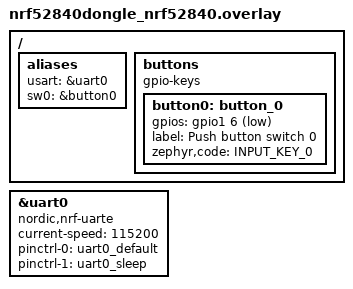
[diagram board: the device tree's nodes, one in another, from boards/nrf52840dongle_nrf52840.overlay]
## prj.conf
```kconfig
CONFIG_GPIO=y
CONFIG_UART_INTERRUPT_DRIVEN=y
CONFIG_STDOUT_CONSOLE=y

CONFIG_SYSTEM_WORKQUEUE_STACK_SIZE=2048

CONFIG_BT_SETTINGS=y
CONFIG_FLASH=y
CONFIG_FLASH_MAP=y
CONFIG_NVS=y
CONFIG_SETTINGS=y
CONFIG_HWINFO=y

CONFIG_BT=y
CONFIG_BT_L2CAP_TX_BUF_COUNT=5
CONFIG_BT_PERIPHERAL=y
CONFIG_BT_OBSERVER=y
CONFIG_BT_BROADCASTER=y

CONFIG_BT_CTLR_DUP_FILTER_LEN=0
CONFIG_BT_CTLR_LE_ENC=n
CONFIG_BT_CTLR_LE_PING=n
CONFIG_BT_DATA_LEN_UPDATE=n
CONFIG_BT_PHY_UPDATE=n
CONFIG_BT_CTLR_MIN_USED_CHAN=n
CONFIG_BT_CTLR_PRIVACY=n
CONFIG_BT_CTLR_CHAN_SEL_2=n

CONFIG_BT_MESH=y
CONFIG_BT_MESH_MODEL_EXTENSIONS=y
CONFIG_BT_MESH_RELAY=y
CONFIG_BT_MESH_FRIEND=y
CONFIG_BT_MESH_PB_GATT=y
CONFIG_BT_MESH_PB_ADV=y
CONFIG_BT_MESH_GATT_PROXY=y

CONFIG_BT_MESH_CFG_CLI=y

#CONFIG_BT_MESH_PROV_OOB_PUBLIC_KEY=y

#CONFIG_BT_MESH_PROV=n
#CONFIG_BT_MESH_PB_ADV=n
#CONFIG_BT_MESH_PB_GATT=n
#CONFIG_BT_MESH_PROV_DEVICE=n
#CONFIG_BT_MESH_PROVISIONER=y

CONFIG_BT_MESH_SUBNET_COUNT=2
CONFIG_BT_MESH_APP_KEY_COUNT=2
CONFIG_BT_MESH_MODEL_GROUP_COUNT=2
CONFIG_BT_MESH_LABEL_COUNT=3
# I don't know if this is all necessary but without it definitely didn't work
```

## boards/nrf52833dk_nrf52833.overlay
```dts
&uart0 {
	compatible = "nordic,nrf-uarte";
	status = "okay";
	current-speed = <115200>;
	pinctrl-0 = <&uart0_default>;
	pinctrl-1 = <&uart0_sleep>;
	pinctrl-names = "default", "sleep";
};

/ {
	aliases {
	usart = &uart0;
	};
};
```

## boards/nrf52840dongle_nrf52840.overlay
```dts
&uart0 {
	compatible = "nordic,nrf-uarte";
	status = "okay";
	current-speed = <115200>;
	pinctrl-0 = <&uart0_default>;
	pinctrl-1 = <&uart0_sleep>;
	pinctrl-names = "default", "sleep";
};

/ {
	aliases {
	usart = &uart0;
	};
};

/{
    buttons {
		compatible = "gpio-keys";
		button0: button_0 {
			gpios = <&gpio1 6 (GPIO_PULL_UP | GPIO_ACTIVE_LOW)>;
			label = "Push button switch 0";
			zephyr,code = <INPUT_KEY_0>;
		};
	};

    aliases {
        sw0 = &button0;
    };
};
```

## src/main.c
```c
#include <zephyr/kernel.h>
#include <zephyr/device.h>
#include <zephyr/drivers/gpio.h>
#include <zephyr/sys/util.h>
#include <zephyr/sys/printk.h>

#include "pcCom.h"
#include "bluetooth.h"
#include "board.h"
#include "uart.h"
#include "group.h"

int main(void)
{
    init();
    k_msleep(1000);
    printk("Starting\n");
    while(1)
    {
        ledSet(true);
        k_msleep(500);
        ledSet(false);
        k_msleep(500);
        readPc();
    }
    return 0;
}

// west build -p always -b nrf52833dk_nrf52833 [location of the project]
```

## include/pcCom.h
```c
#ifndef PCCOM_H_
#define PCCOM_H_

void readPc();

#endif // PCCOM_H_
```

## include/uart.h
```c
#ifndef UART_H_
#define UART_H_

extern struct k_msgq uart_msgq; // Declare uart_msgq here

int uartSetup(void);

#endif //UART_H_
```

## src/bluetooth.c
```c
/* main.c - Application main entry point */

/*
 * Copyright (c) 2017 Intel Corporation
 *
 * SPDX-License-Identifier: Apache-2.0
 */

#include <zephyr/sys/printk.h>

#include <zephyr/settings/settings.h>
#include <zephyr/devicetree.h>
#include <zephyr/device.h>
#include <zephyr/drivers/gpio.h>
#include <zephyr/drivers/hwinfo.h>
#include <zephyr/sys/byteorder.h>

#include <zephyr/bluetooth/bluetooth.h>
#include <zephyr/bluetooth/mesh.h>

#include "board.h"
#include "bluetooth.h"

uint16_t extern_net_idx = 0;
uint16_t extern_addr = 0;

#define OP_ONOFF_GET       BT_MESH_MODEL_OP_2(0x82, 0x01)
#define OP_ONOFF_SET       BT_MESH_MODEL_OP_2(0x82, 0x02)
#define OP_ONOFF_SET_UNACK BT_MESH_MODEL_OP_2(0x82, 0x03)
#define OP_ONOFF_STATUS    BT_MESH_MODEL_OP_2(0x82, 0x04)

static void attention_on(struct bt_mesh_model *mod)
{
	ledSet(true);
}

static void attention_off(struct bt_mesh_model *mod)
{
	ledSet(false);
}

static const struct bt_mesh_health_srv_cb health_cb = {
	.attn_on = attention_on,
	.attn_off = attention_off,
};

static struct bt_mesh_health_srv health_srv = {
	.cb = &health_cb,
};

BT_MESH_HEALTH_PUB_DEFINE(health_pub, 0);

static const char *const onoff_str[] = { "off", "on" };

static struct {
	bool val;
	uint8_t tid;
	uint16_t src;
	uint32_t transition_time;
	struct k_work_delayable work;
} onoff;

/* OnOff messages' transition time and remaining time fields are encoded as an
 * 8 bit value with a 6 bit step field and a 2 bit resolution field.
 * The resolution field maps to:
 * 0: 100 ms
 * 1: 1 s
 * 2: 10 s
 * 3: 20 min
 */
static const uint32_t time_res[] = {
	100,
	MSEC_PER_SEC,
	10 * MSEC_PER_SEC,
	10 * 60 * MSEC_PER_SEC,
};

static inline int32_t model_time_decode(uint8_t val)
{
	uint8_t resolution = (val >> 6) & BIT_MASK(2);
	uint8_t steps = val & BIT_MASK(6);

	if (steps == 0x3f) {
		return SYS_FOREVER_MS;
	}

	return steps * time_res[resolution];
}

static inline uint8_t model_time_encode(int32_t ms)
{
	if (ms == SYS_FOREVER_MS) {
		return 0x3f;
	}

	for (int i = 0; i < ARRAY_SIZE(time_res); i++) {
		if (ms >= BIT_MASK(6) * time_res[i]) {
			continue;
		}

		uint8_t steps = DIV_ROUND_UP(ms, time_res[i]);

		return steps | (i << 6);
	}

	return 0x3f;
}

bool onoffVal()
{
	return onoff.val;
}

static int onoff_status_send(struct bt_mesh_model *model, struct bt_mesh_msg_ctx *ctx) // send onoff status to all nodes in the ctx group
{
	uint32_t remaining;

	BT_MESH_MODEL_BUF_DEFINE(buf, OP_ONOFF_STATUS, 3);
	bt_mesh_model_msg_init(&buf, OP_ONOFF_STATUS);

	remaining = k_ticks_to_ms_floor32(
			    k_work_delayable_remaining_get(&onoff.work)) +
		    onoff.transition_time;

	/* Check using remaining time instead of "work pending" to make the
	 * onoff status send the right value on instant transitions. As the
	 * work item is executed in a lower priority than the mesh message
	 * handler, the work will be pending even on instant transitions.
	 */
	if (remaining) {
		net_buf_simple_add_u8(&buf, !onoff.val);
		net_buf_simple_add_u8(&buf, onoff.val);
		net_buf_simple_add_u8(&buf, model_time_encode(remaining));
	} else {
		net_buf_simple_add_u8(&buf, onoff.val);
	}

	return bt_mesh_model_send(model, ctx, &buf, NULL, NULL);
}

static void onoff_timeout(struct k_work *work)
{
	if (onoff.transition_time) {
		/* Start transition.
		 *
		 * The LED should be on as long as the transition is in
		 * progress, regardless of the target value, according to the
		 * Bluetooth Mesh Model specification, section 3.1.1.
		 */
		ledSet(true);

		k_work_reschedule(&onoff.work, K_MSEC(onoff.transition_time));
		onoff.transition_time = 0;
		return;
	}

	ledSet(onoff.val);
}

/* Generic OnOff Server message handlers */


static int gen_onoff_get(struct bt_mesh_model *model,
			 struct bt_mesh_msg_ctx *ctx,
			 struct net_buf_simple *buf)
{
	onoff_status_send(model, ctx);
	return 0;
}

static int gen_onoff_set_unack(struct bt_mesh_model *model,
			       struct bt_mesh_msg_ctx *ctx,
			       struct net_buf_simple *buf)
{
	uint8_t val = net_buf_simple_pull_u8(buf);
	uint8_t tid = net_buf_simple_pull_u8(buf);
	int32_t trans = 0;
	int32_t delay = 0;

	if (buf->len) {
		trans = model_time_decode(net_buf_simple_pull_u8(buf));
		delay = net_buf_simple_pull_u8(buf) * 5;
	}

	/* Only perform change if the message wasn't a duplicate and the
	 * value is different.
	 */
	if (tid == onoff.tid && ctx->addr == onoff.src) {
		/* Duplicate */
		return 0;
	}

	// if (val == onoff.val) {
	// 	/* No change */
	// 	return 0;
	// }

	printk("set: %s delay: %d ms time: %d ms\n", onoff_str[val], delay,
	       trans);

	onoff.tid = tid;
	onoff.src = ctx->addr;
	onoff.val = !onoff.val;
	onoff.transition_time = trans;

	/* Schedule the next action to happen on the delay, and keep
	 * transition time stored, so it can be applied in the timeout.
	 */
	k_work_reschedule(&onoff.work, K_MSEC(delay));

	return 0;
}

static int gen_onoff_set(struct bt_mesh_model *model,
			 struct bt_mesh_msg_ctx *ctx,
			 struct net_buf_simple *buf)
{
	(void)gen_onoff_set_unack(model, ctx, buf);
	onoff_status_send(model, ctx);

	return 0;
}

static const struct bt_mesh_model_op gen_onoff_srv_op[] = {
	{ OP_ONOFF_GET,       BT_MESH_LEN_EXACT(0), gen_onoff_get },
	{ OP_ONOFF_SET,       BT_MESH_LEN_MIN(2),   gen_onoff_set },
	{ OP_ONOFF_SET_UNACK, BT_MESH_LEN_MIN(2),   gen_onoff_set_unack },
	BT_MESH_MODEL_OP_END,
};

/* Generic OnOff Client */

static int gen_onoff_status(struct bt_mesh_model *model,
			    struct bt_mesh_msg_ctx *ctx,
			    struct net_buf_simple *buf)
{
	uint8_t present = net_buf_simple_pull_u8(buf);

	if (buf->len) {
		uint8_t target = net_buf_simple_pull_u8(buf);
		int32_t remaining_time =
			model_time_decode(net_buf_simple_pull_u8(buf));

		printk("OnOff status: %s -> %s: (%d ms)\n", onoff_str[present],
		       onoff_str[target], remaining_time);
		return 0;
	}

	printk("OnOff status: %s\n", onoff_str[present]);

	return 0;
}

static const struct bt_mesh_model_op gen_onoff_cli_op[] = {
	{OP_ONOFF_STATUS, BT_MESH_LEN_MIN(1), gen_onoff_status},
	BT_MESH_MODEL_OP_END,
};

/* This application only needs one element to contain its models */
static struct bt_mesh_model models[] = {
	BT_MESH_MODEL_CFG_SRV,
	BT_MESH_MODEL_HEALTH_SRV(&health_srv, &health_pub),
	BT_MESH_MODEL(BT_MESH_MODEL_ID_GEN_ONOFF_SRV, gen_onoff_srv_op, NULL,
		      NULL),
	BT_MESH_MODEL(BT_MESH_MODEL_ID_GEN_ONOFF_CLI, gen_onoff_cli_op, NULL,
		      NULL),
};

static struct bt_mesh_elem elements[] = {
	BT_MESH_ELEM(0, models, BT_MESH_MODEL_NONE),
};

static const struct bt_mesh_comp comp = {
	.cid = BT_COMP_ID_LF,
	.elem = elements,
	.elem_count = ARRAY_SIZE(elements),
};

/* Provisioning */

static int output_number(bt_mesh_output_action_t action, uint32_t number)
{
	printk("OOB Number: %u\n", number);

	boardOutputNumber(action, number);

	return 0;
}

void clear_provisioning_data(void)
{
    int err;

    // Clear provisioning data from settings
    err = settings_delete("bt/mesh");
    if (err) {
        printk("Failed to clear provisioning data (err %d)\n", err);
        return;
    }

    printk("Provisioning data cleared\n");
}

static void prov_complete(uint16_t net_idx, uint16_t addr)
{
	extern uint16_t extern_net_idx;
	extern uint16_t extern_addr;
	extern_net_idx = net_idx;
	extern_addr = addr;
	boardProvComplete();
	for(int i = 0; i < models[3].groups_cnt; i++)
	{
		printk("Group address %d\n", models[3].groups[i]);
	}
	printk("Provisioning completed. Network Index: 0x%04x, Address: 0x%04x\n",
           net_idx, addr);
}

static void prov_reset(void)
{
	bt_mesh_prov_disable(BT_MESH_PROV_ADV | BT_MESH_PROV_GATT | BT_MESH_PROV_REMOTE);//disable mesh provisioning
	clear_provisioning_data();//reset provisioning data
	bt_mesh_prov_enable(BT_MESH_PROV_ADV | BT_MESH_PROV_GATT);
	//bt_mesh_prov_enable(BT_MESH_PROV_ADV | BT_MESH_PROV_GATT);
}

static uint8_t dev_uuid[16];

static const struct bt_mesh_prov prov = {
	.uuid = dev_uuid,
	.output_size = 4,
	.output_actions = BT_MESH_DISPLAY_NUMBER,
	.output_number = output_number,
	.complete = prov_complete,
	.reset = prov_reset,
};

void getNetIdx(uint16_t *input) // get network index
{
	extern uint16_t extern_net_idx;
	*input = extern_net_idx;
}

uint16_t getAddr() // get address of the device (simplified)
{
	extern uint16_t extern_addr;
	return extern_addr;
}

uint16_t getElem(uint8_t index)
{
    return getAddr() + index;
}

uint16_t getGroup(uint16_t groupNr) // not used but useful for understanding how to get groups
{
	return models[3].groups[groupNr];
}

/** Send an OnOff Set message from the Generic OnOff Client to all nodes. */
extern int gen_onoff_send(bool val, uint16_t groupAddress)
{
	struct bt_mesh_msg_ctx ctx = {
		.app_idx = models[3].keys[0], /* Use the bound key */
		.addr = groupAddress, 
		.send_ttl = BT_MESH_TTL_DEFAULT,
	};
	static uint8_t tid;

	if (ctx.app_idx == BT_MESH_KEY_UNUSED) {
		printk("The Client must be bound to a key before "
		       "sending.\n");
		return -ENOENT;
	}

	BT_MESH_MODEL_BUF_DEFINE(buf, OP_ONOFF_SET_UNACK, 2);
	bt_mesh_model_msg_init(&buf, OP_ONOFF_SET_UNACK);
	net_buf_simple_add_u8(&buf, val);
	net_buf_simple_add_u8(&buf, tid++);

	printk("Sending OnOff Set: %s\n", onoff_str[val]);

	return bt_mesh_model_send(&models[3], &ctx, &buf, NULL, NULL);
}

void btnPressed()
{
	printk("amount of groups 2: %d\n", models[2].groups_cnt);
	printk("amount of groups 3: %d\n", models[3].groups_cnt);	
	if (bt_mesh_is_provisioned()) 
	{
		for(int i = 0; i < models[3].groups_cnt; i++)
		{
			printk("Group address %d\n", models[3].groups[i]);
			(void)gen_onoff_send(!onoff.val, models[3].groups[i]);
		}
		return;
	}

	static uint8_t net_key[16];
	static uint8_t dev_key[16];
	static uint8_t app_key[16];
	uint16_t addr;
	int err;

	if (IS_ENABLED(CONFIG_HWINFO)) {
		addr = sys_get_le16(&dev_uuid[0]) & BIT_MASK(15);
	} else {
		addr = k_uptime_get_32() & BIT_MASK(15);
	}

	printk("Self-provisioning with address 0x%04x\n", addr);
	err = bt_mesh_provision(net_key, 0, 0, 0, addr, dev_key);
	if (err) {
		printk("Provisioning failed (err: %d)\n", err);
		return;
	}

	// Add an application key to both Generic OnOff models: 
	err = bt_mesh_app_key_add(0, 0, app_key);
	if (err) {
		printk("App key add failed (err: %d)\n", err);
		return;
	}

	/* Models must be bound to an app key to send and receive messages with
	 * it:
	 *//*
	models[2].keys[0] = 0;
	models[3].keys[0] = 0;

	printk("Provisioned and configured!\n");*/
}

static void bt_ready(int err)
{
	if (err) {
		printk("Bluetooth init failed (err %d)\n", err);
		return;
	}

	printk("Bluetooth initialized\n");


	err = bt_mesh_init(&prov, &comp);
	if (err) {
		printk("Initializing mesh failed (err %d)\n", err);
		return;
	}

	if (IS_ENABLED(CONFIG_SETTINGS)) {
		printk("Loading stored settings\n");
		settings_load(); // WATCH OUT: CRASHES HERE!!!
			printk("Got to here\n");
	} else {
		printk("uhoh\n");
	}


	/* This will be a no-op if settings_load() loaded provisioning info */
	//bt_mesh_prov_enable(BT_MESH_PROV_ADV | BT_MESH_PROV_GATT); // for self provisioning
	bt_mesh_prov_enable(BT_MESH_PROV_ADV | BT_MESH_PROV_GATT);

	printk("Mesh initialized\n");
}

int bluetoothInit(void)
{
	int err = -1;

	printk("Initializing...\n");

	if (IS_ENABLED(CONFIG_HWINFO)) {
		err = hwinfo_get_device_id(dev_uuid, sizeof(dev_uuid));
	}

	if (err < 0) {
		dev_uuid[0] = 0xdd;
		dev_uuid[1] = 0xdd;
	}

	k_work_init_delayable(&onoff.work, onoff_timeout);

	/* Initialize the Bluetooth Subsystem */
	err = bt_enable(bt_ready);
	if (err) {
		printk("Bluetooth init failed (err %d)\n", err);
	}
	return 0;
}
```

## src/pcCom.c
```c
#include "uart.h"
#include "bluetooth.h"
#include "pcCom.h"
#include "board.h"
#include "group.h"	// Contains the subscribeToGroup functions etc.

#include <zephyr/kernel.h>
#include <zephyr/device.h>
#include <zephyr/drivers/uart.h>
#include <zephyr/sys/printk.h>
#include <stdbool.h>
#include <string.h>
#include <stdlib.h>

#define MESSAGE_SIZE 256 // Defines the maximum size for the incoming string

#define MAX_NAMES 256
#define MAX_NAME_LENGTH 13

static char names[MAX_NAMES][MAX_NAME_LENGTH];
static int nameCount = 0;
static uint16_t groupAddresses[MAX_NAMES];

static int mr = 0;

//readPC functions
void caseConnected(char *Message)
{
    char onoff[] = {"false"};
    if(onoffVal())
    {
        strcpy(onoff, "true");
    }
    printk("Connection established\n");
    printk("AddNode PcNode %05d %05d AddSensor Button pcButton AddActuator LED pcLED %s\n", getAddr(), getElem(0), onoff);
    for (int i = 0; i < nameCount; i++)
    {
        printk("AddGroup %d %s\n", groupAddresses[i], names[i]); // Group 49152 [groupname]
        k_msleep(10);
    }
}

void deleteGroup(char *Message)
{
    int index_to_delete = -1;

    // Find the index of the group to delete
    for (int i = 0; i < nameCount; i++) {
        if (groupAddresses[i] == atoi(Message)) {
            index_to_delete = i;
            break;
        }
    }

    // If the group was not found, return
    if (index_to_delete == -1) {
        return;
    }

    // Shift all elements after the index to delete one position to the left
    for (int i = index_to_delete; i < nameCount - 1; i++) {
        groupAddresses[i] = groupAddresses[i + 1];
        strcpy(names[i], names[i + 1]);
    }

    // Decrease the count of names
    nameCount--;
}

void createGroupFinal(char *Message, int i)
{
    groupAddresses[i] = atoi(Message); // address of the group that is being created
    memmove(Message, Message + 6, strlen(Message) - 6 + 1); //removes create_group_ from message
    strcpy(names[i], Message);
}

void createGroup(char *Message)
{
    for(int i = 0; i < nameCount; i++)
    {
        if(groupAddresses[i] == atoi(Message) && strstr(Message, names[i]))
        {
            printk("Group already exists\n");
            return;
        }
        else if(groupAddresses[i] == atoi(Message) && !strstr(Message, names[i]))
        {
            createGroupFinal(Message, i);
            return;
        }
    }
    createGroupFinal(Message, nameCount);
    nameCount++;
}

void groupToggle(char *Message)
{
    uint16_t groupAddress = atoi(Message);

    printk("Toggling group %04x\n", groupAddress);
    gen_onoff_send(!onoffVal(), groupAddress); //send onoff message to group
}

void uartSubscribeGroup(char *Message, bool sub)
{
    printk("Message: %s\n", Message);
    uint16_t netKeyIndex = 0x0002;
    uint16_t groupAddress = atoi(Message); // address of the group that is being subscribed to
    memmove(Message, Message + 6, strlen(Message) - 6 + 1);
    uint16_t elementAddress = atoi(Message); // element address of the device that is subscribing to the group
    memmove(Message, Message + 6, strlen(Message) - 6 + 1);
    uint16_t mod_id = atoi(Message); // model id of the device that is subscribing to the group
    memmove(Message, Message + 6, strlen(Message) - 6 + 1);
    uint16_t address = atoi(Message); // address of the device that is subscribing to the group

    printk("Subscribing to group %04x\n", groupAddress);
    getNetIdx(&netKeyIndex);
    k_msleep(1); // wait for netKeyIndex to be set
    printk("netKeyIndex: %04x\n", netKeyIndex);	
    printk("index: 0x%04x, address: 0x%04x, elementAddress: 0x%04x, groupAddress: 0x%04x, mod_id: 0x%04x\n", netKeyIndex, address, elementAddress, groupAddress, mod_id);
    if(sub)
        subscribeToGroup(groupAddress, elementAddress, mod_id, netKeyIndex, address);
    else
        unsubscribeFromGroup(groupAddress, elementAddress, mod_id, netKeyIndex, address);
}

// Reads input from the application and decides what to do with it
void readPc()
{
    char Message[MESSAGE_SIZE];

    // Clear the message array
    for (int i = 0; i < MESSAGE_SIZE; i++)
    {
        Message[i] = '\0';
    }

    k_msgq_get(&uart_msgq, &Message, K_NO_WAIT);
    k_msgq_cleanup(&uart_msgq);

    // Send out already existing groups
    if (strstr(Message, "connected"))
    {
        caseConnected(Message);
        mr = 1;
    } 
    else if(strstr(Message, "toggle_group_")) // checks for "toggle_group" in the message	
    {
        memmove(Message, Message + 13 + mr, strlen(Message) - 13 + mr + 1); //removes toggle_group_ from message
        groupToggle(Message);
        mr = 1;
    }
    else if(strstr(Message, "unsubscribe_group_"))
    {
        memmove(Message, Message + 18 + mr, strlen(Message) - 18 + mr + 1); //removes unsubscribe_group_ from message
        // printk("Message: %s\n", Message);
        uartSubscribeGroup(Message, false);
        mr = 1;
    }
    else if(strstr(Message, "subscribe_group_"))
    {
        memmove(Message, Message + 16+ mr, strlen(Message) - 16 + mr + 1); //removes subscribe_group_ from message
        // printk("Message: %s\n", Message);
        uartSubscribeGroup(Message, true);
        mr = 1;
    }
    else if(strstr(Message, "create_group_"))
    {
        memmove(Message, Message + 13 + mr, strlen(Message) - 13 + mr + 1); //removes create_group_ from message
        createGroup(Message);
        mr = 1;
    }
    else if(strstr(Message, "delete_group_"))
    {
        memmove(Message, Message + 13 + mr, strlen(Message) - 13 + mr + 1); //removes delete_group_ from message
        deleteGroup(Message);
        mr = 1;
    }
    else if(strlen(Message) > 0) // if the message is not empty and does not contain any of the above defined commands
    {
        printk("Unknown command\n");
        mr = 1;
    }
    k_msgq_cleanup(&uart_msgq);
}
```

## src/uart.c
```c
#include <string.h>
#include <zephyr/kernel.h>
#include <zephyr/device.h>
#include <zephyr/drivers/uart.h>
#include "uart.h"

//Setup uart connection to pc
#define UART_DEVICE_NODE DT_ALIAS(usart)
static const struct device *const uart_dev = DEVICE_DT_GET(UART_DEVICE_NODE);

//Data retrieval
#define MSG_SIZE 128
static char rx_buf[MSG_SIZE];
static int rx_buf_pos;

//Define msgq
K_MSGQ_DEFINE(uart_msgq, MSG_SIZE, 10, 4);

//Needed to read data from uart
void serial_cb(const struct device *dev, void *user_data)
{
	uint8_t c;

	if (!uart_irq_update(uart_dev))
	{
		return;
	}

	if (!uart_irq_rx_ready(uart_dev))
	{
		return;
	}

	// read until FIFO empty 
	while (uart_fifo_read(uart_dev, &c, 1) == 1)
	{
		if ((c == '\n' || c == '\r') && rx_buf_pos > 0)
		{
			// terminate string 
			rx_buf[rx_buf_pos] = '\0';

			// if queue is full, message is silently dropped 
			k_msgq_put(&uart_msgq, &rx_buf, K_NO_WAIT);

			// reset the buffer (it was copied to the msgq) 
			rx_buf_pos = 0;
		}
		else if (rx_buf_pos < (sizeof(rx_buf) - 1))
		{
			rx_buf[rx_buf_pos++] = c;
		}
		// else: characters beyond buffer size are dropped 
	}
}

//Setup uart device
int uartSetup()
{
	if (!device_is_ready(uart_dev))
	{
		printk("UART device not found!\n");
		return -1;
	} else
    {
        printk("UART device found!\n");
    }

	/* configure interrupt and callback to receive data */
    
	int ret = uart_irq_callback_user_data_set(uart_dev, serial_cb, NULL);

	if (ret < 0)
	{
		if (ret == -ENOTSUP)
		{
			printk("Interrupt-driven UART API support not enabled\n");
		}
		else if (ret == -ENOSYS)
		{
			printk("UART device does not support interrupt-driven API\n");
		}
		else
		{
			printk("Error setting UART callback: %d\n", ret);
		}
		return -1;
	}

	uart_irq_rx_enable(uart_dev);
	return 0;
}
```
